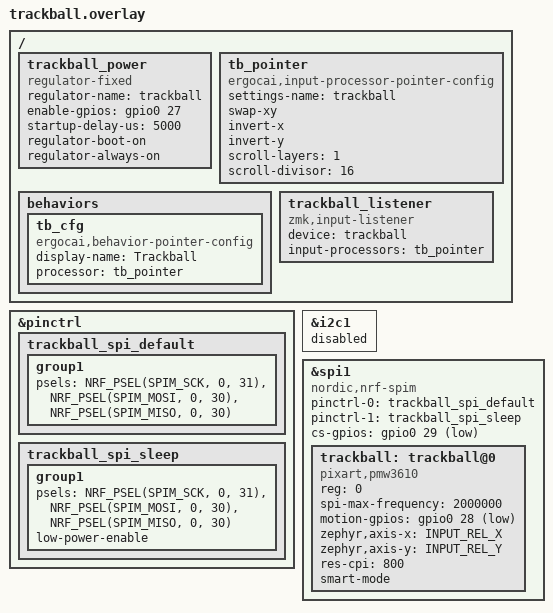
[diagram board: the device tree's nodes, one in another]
/*
 * The trackball module (ErgoCai.modules trackball/PMW3610-pogo) on the joystick module's mount
 * (joystick-mount-pogo): a PixArt PMW3610DM-SUDU on 3-wire SPI, through Zephyr's pixart,pmw3610 driver.
 * The pins below are stand-ins: zmk-config's config/<half>.overlay, which kbplacer writes after routing, sets them
 * (SCLK, SDIO, NCS, MOTION and the module's supply), under #ifdef SHIELD_TRACKBALL.
 * - SDIO is one wire for both ways: the SPIM's MOSI and MISO on the same pin, as the PMW3610 builds on the
 *   nRF52840 do (Zephyr's nRF SPIM has no half-duplex mode).
 * - The module's supply is a GPIO (the stick's, switched there only while sampling): a fixed regulator turns it
 *   on at boot and keeps it on; the sensor draws 0.6 mA when running (datasheet table 4), its LDO makes 1.8 V.
 * - The sensor sits a quarter turn round on the module board, its back to the board, and the module (and the
 *   trackball on the keyboard board alike) goes on the keyboard turned half a turn, its pins by the thumb: the
 *   pointer settings below (tb_pointer) swap the axes and invert both by default. The &tb_cfg key (ZMK Studio:
 *   "Trackball") flips x or y, swaps them or changes the speed while the keyboard runs, and the settings keep it:
 *   the side-read trackball's sensor reads the ball's side, so it may need a flip or a swap of its own.
 */

#include <dt-bindings/gpio/nordic-nrf-gpio.h>
#include <dt-bindings/zmk/input_transform.h>
#include <dt-bindings/zmk/pointer_config.h>
#include <input/processors.dtsi>
#include <zephyr/dt-bindings/input/input-event-codes.h>

/* user config can test #ifdef SHIELD_TRACKBALL */
#define SHIELD_TRACKBALL

/ {
    trackball_power: trackball_power {
        compatible = "regulator-fixed";
        regulator-name = "trackball";
        enable-gpios = <&gpio0 27 (GPIO_ACTIVE_HIGH | NRF_GPIO_DRIVE_H0H1)>;
        /* the LDO's output settled before the driver's power-up reset; the regulator's init runs first */
        startup-delay-us = <5000>;
        regulator-boot-on;
        regulator-always-on;
    };

    tb_pointer: tb_pointer {
        compatible = "ergocai,input-processor-pointer-config";
        #input-processor-cells = <0>;
        settings-name = "trackball";
        swap-xy;
        invert-x;
        invert-y;
        /* on layer 1 the ball scrolls (16 times slower); a key changes any layer's mode */
        scroll-layers = <1>;
        scroll-divisor = <16>;
    };

    behaviors {
        tb_cfg: tb_cfg {
            compatible = "ergocai,behavior-pointer-config";
            #binding-cells = <1>;
            display-name = "Trackball";
            processor = <&tb_pointer>;
        };
    };

    trackball_listener: trackball_listener {
        compatible = "zmk,input-listener";
        device = <&trackball>;
        input-processors = <&tb_pointer>;
    };
};

&pinctrl {
    trackball_spi_default: trackball_spi_default {
        group1 {
            psels = <NRF_PSEL(SPIM_SCK, 0, 31)>,
                    <NRF_PSEL(SPIM_MOSI, 0, 30)>,
                    <NRF_PSEL(SPIM_MISO, 0, 30)>;
        };
    };

    trackball_spi_sleep: trackball_spi_sleep {
        group1 {
            psels = <NRF_PSEL(SPIM_SCK, 0, 31)>,
                    <NRF_PSEL(SPIM_MOSI, 0, 30)>,
                    <NRF_PSEL(SPIM_MISO, 0, 30)>;
            low-power-enable;
        };
    };
};

/* SPIM1: the e-paper module takes SPIM2 (display) and SPIM3 (LED); TWIM1, which shares SPIM1, stays off */
&i2c1 {
    status = "disabled";
};

trackball_spi: &spi1 {
    status = "okay";
    compatible = "nordic,nrf-spim";
    pinctrl-0 = <&trackball_spi_default>;
    pinctrl-1 = <&trackball_spi_sleep>;
    pinctrl-names = "default", "sleep";
    cs-gpios = <&gpio0 29 GPIO_ACTIVE_LOW>;

    trackball: trackball@0 {
        compatible = "pixart,pmw3610";
        reg = <0>;
        spi-max-frequency = <2000000>;
        motion-gpios = <&gpio0 28 (GPIO_ACTIVE_LOW | GPIO_PULL_UP)>;
        zephyr,axis-x = <INPUT_REL_X>;
        zephyr,axis-y = <INPUT_REL_Y>;
        res-cpi = <800>;
        smart-mode;
    };
};
